# iospear310 register map
Registers from a debugger description file.
Registers are 32-bit, access not given, no defined reset value unless marked. A register's access mark holds for its fields unless they carry their own. Addresses are absolute; registers are grouped by the start of their names; lines under a group give offsets from that group; [hi:lo] are bit positions; {n}, {i} and the like mark numbered series; 'fields as' and 'values as' point back to an identical list; <NAME> marks a mode.

## PLL1
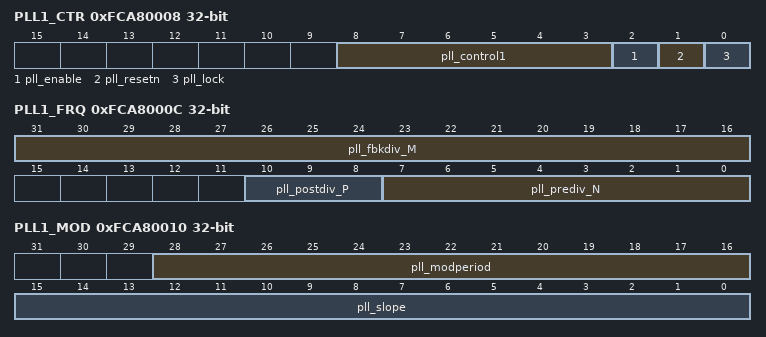
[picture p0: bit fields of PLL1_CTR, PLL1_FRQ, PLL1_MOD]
0xFCA80008 PLL1_CTR
  [8:3] pll_control1, [2] pll_enable, [1] pll_resetn, [0] pll_lock
0xFCA8000C PLL1_FRQ
  [31:16] pll_fbkdiv_M, [10:8] pll_postdiv_P, [7:0] pll_prediv_N
0xFCA80010 PLL1_MOD
  [28:16] pll_modperiod, [15:0] pll_slope

## PLL2
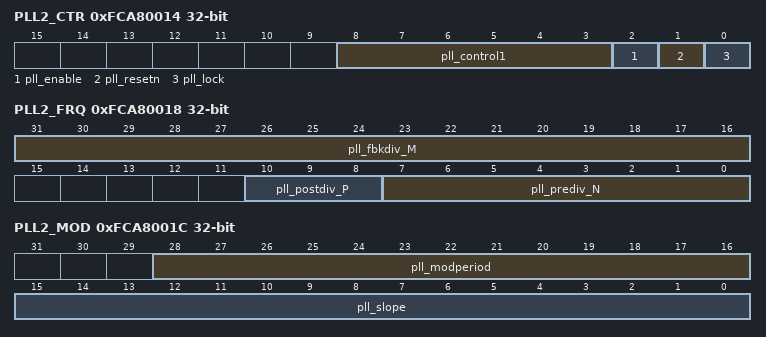
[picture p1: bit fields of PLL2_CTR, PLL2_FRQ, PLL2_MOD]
0xFCA80014 PLL2_CTR
  [8:3] pll_control1, [2] pll_enable, [1] pll_resetn, [0] pll_lock
0xFCA80018 PLL2_FRQ
  [31:16] pll_fbkdiv_M, [10:8] pll_postdiv_P, [7:0] pll_prediv_N
0xFCA8001C PLL2_MOD
  [28:16] pll_modperiod, [15:0] pll_slope

## PERIP1
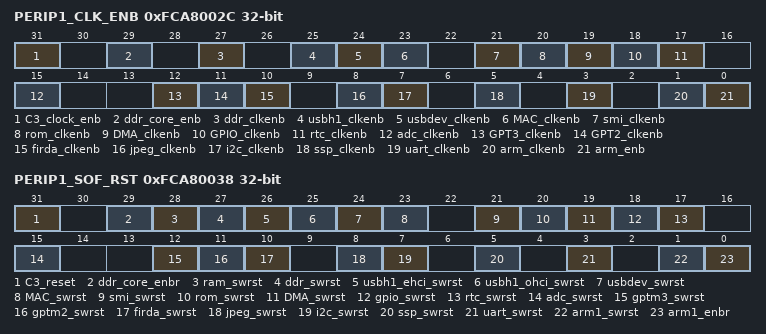
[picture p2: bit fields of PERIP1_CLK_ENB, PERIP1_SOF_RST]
0xFCA8002C PERIP1_CLK_ENB
  [31] C3_clock_enb, [29] ddr_core_enb, [27] ddr_clkenb, [25] usbh1_clkenb, [24] usbdev_clkenb, [23] MAC_clkenb, [21] smi_clkenb, [20] rom_clkenb, [19] DMA_clkenb, [18] GPIO_clkenb, [17] rtc_clkenb, [15] adc_clkenb, [12] GPT3_clkenb, [11] GPT2_clkenb, [10] firda_clkenb, [8] jpeg_clkenb, [7] i2c_clkenb, [5] ssp_clkenb, [3] uart_clkenb, [1] arm_clkenb, [0] arm_enb
0xFCA80038 PERIP1_SOF_RST
  [31] C3_reset, [29] ddr_core_enbr, [28] ram_swrst, [27] ddr_swrst, [26] usbh1_ehci_swrst, [25] usbh1_ohci_swrst, [24] usbdev_swrst, [23] MAC_swrst, [21] smi_swrst, [20] rom_swrst, [19] DMA_swrst, [18] gpio_swrst, [17] rtc_swrst, [15] adc_swrst, [12] gptm3_swrst, [11] gptm2_swrst, [10] firda_swrst, [8] jpeg_swrst, [7] i2c_swrst, [5] ssp_swrst, [3] uart_swrst, [1] arm1_swrst, [0] arm1_enbr

## RAS
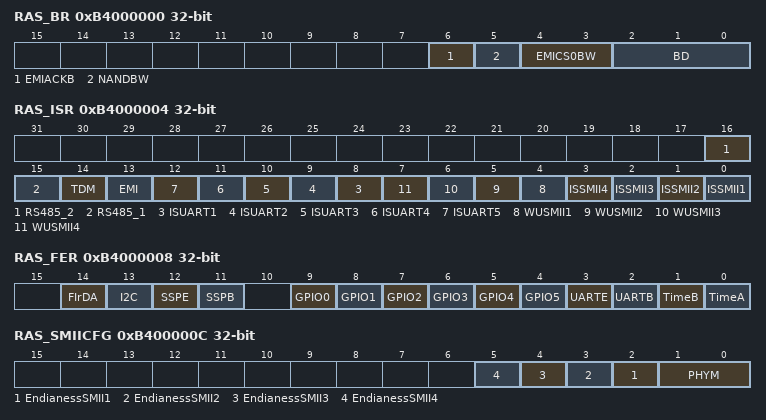
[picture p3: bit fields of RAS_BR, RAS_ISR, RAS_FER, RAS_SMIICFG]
0xB4000000 RAS_BR
  [6] EMIACKB, [5] NANDBW, [4:3] EMICS0BW, [2:0] BD
0xB4000004 RAS_ISR
  [16] RS485_2, [15] RS485_1, [14] TDM, [13] EMI, [n+7] ISUART{n} (n=1..5), [n+3] WUSMII{n} (n=1..4), [n-1] ISSMII{n} (n=1..4)
0xB4000008 RAS_FER
  [14] FIrDA, [13] I2C, [12] SSPE, [11] SSPB, [9-n] GPIO{n} (n=0..5), [3] UARTE, [2] UARTB, [1] TimeB, [0] TimeA
0xB400000C RAS_SMIICFG
  [n+1] EndianessSMII{n} (n=1..4), [1:0] PHYM
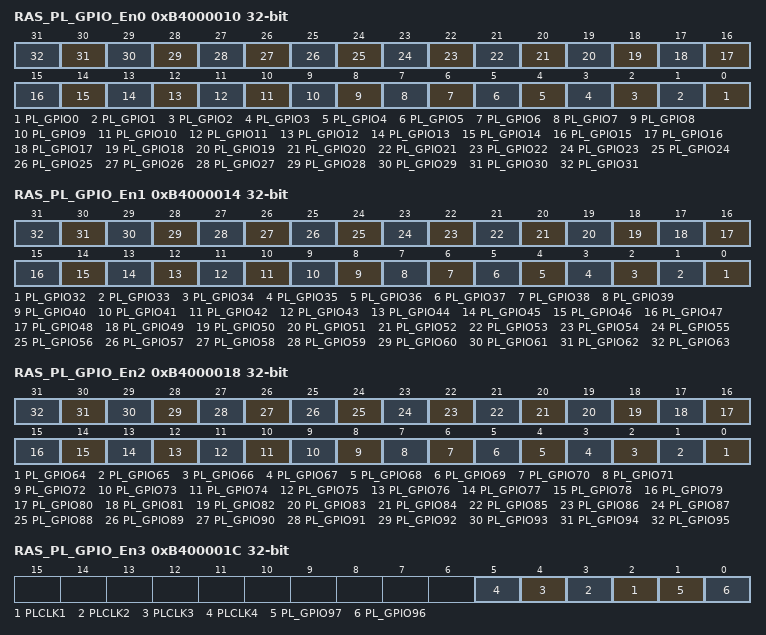
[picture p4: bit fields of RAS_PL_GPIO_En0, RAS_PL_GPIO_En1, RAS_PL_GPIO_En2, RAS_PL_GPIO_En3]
0xB4000010 RAS_PL_GPIO_En0
  [n] PL_GPIO{n} (n=0..31)
0xB4000014 RAS_PL_GPIO_En1
  [n-32] PL_GPIO{n} (n=32..63)
0xB4000018 RAS_PL_GPIO_En2
  [n-64] PL_GPIO{n} (n=64..95)
0xB400001C RAS_PL_GPIO_En3
  [n+1] PLCLK{n} (n=1..4), [1] PL_GPIO97, [0] PL_GPIO96
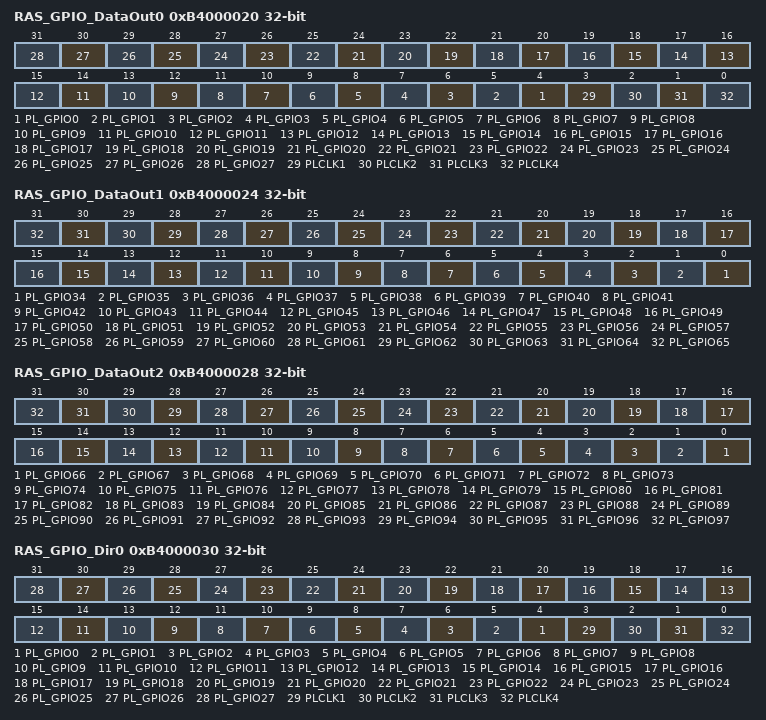
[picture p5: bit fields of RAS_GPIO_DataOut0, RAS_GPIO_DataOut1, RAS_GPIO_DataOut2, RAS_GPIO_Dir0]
0xB4000020 RAS_GPIO_DataOut0
  [n+4] PL_GPIO{n} (n=0..27), [4-n] PLCLK{n} (n=1..4)
0xB4000024 RAS_GPIO_DataOut1
  [n-34] PL_GPIO{n} (n=34..65)
0xB4000028 RAS_GPIO_DataOut2
  [n-66] PL_GPIO{n} (n=66..97)
0xB4000030 RAS_GPIO_Dir0
  [n+4] PL_GPIO{n} (n=0..27), [4-n] PLCLK{n} (n=1..4)
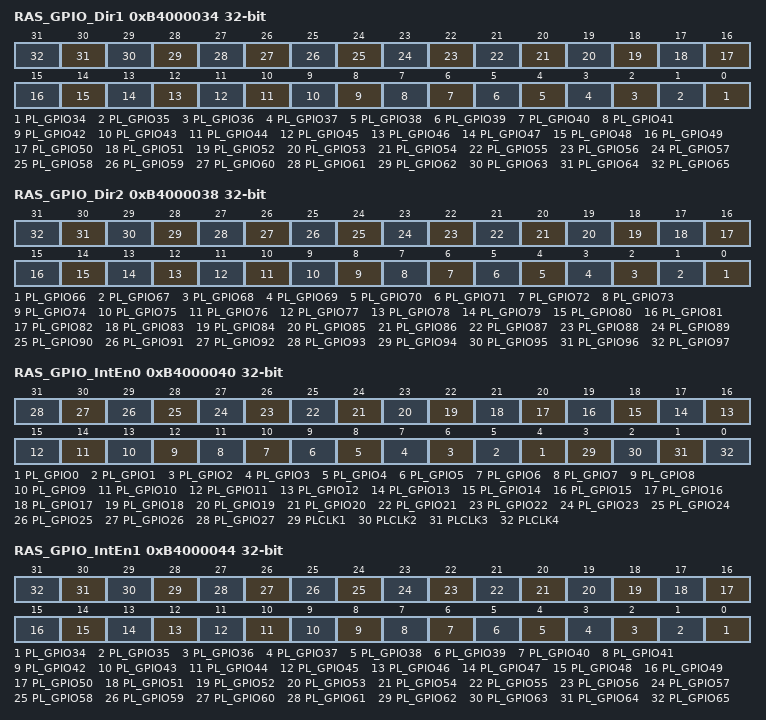
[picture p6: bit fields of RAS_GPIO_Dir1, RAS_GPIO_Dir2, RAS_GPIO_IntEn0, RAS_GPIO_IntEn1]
0xB4000034 RAS_GPIO_Dir1
  [n-34] PL_GPIO{n} (n=34..65)
0xB4000038 RAS_GPIO_Dir2
  [n-66] PL_GPIO{n} (n=66..97)
0xB4000040 RAS_GPIO_IntEn0
  [n+4] PL_GPIO{n} (n=0..27), [4-n] PLCLK{n} (n=1..4)
0xB4000044 RAS_GPIO_IntEn1
  [n-34] PL_GPIO{n} (n=34..65)
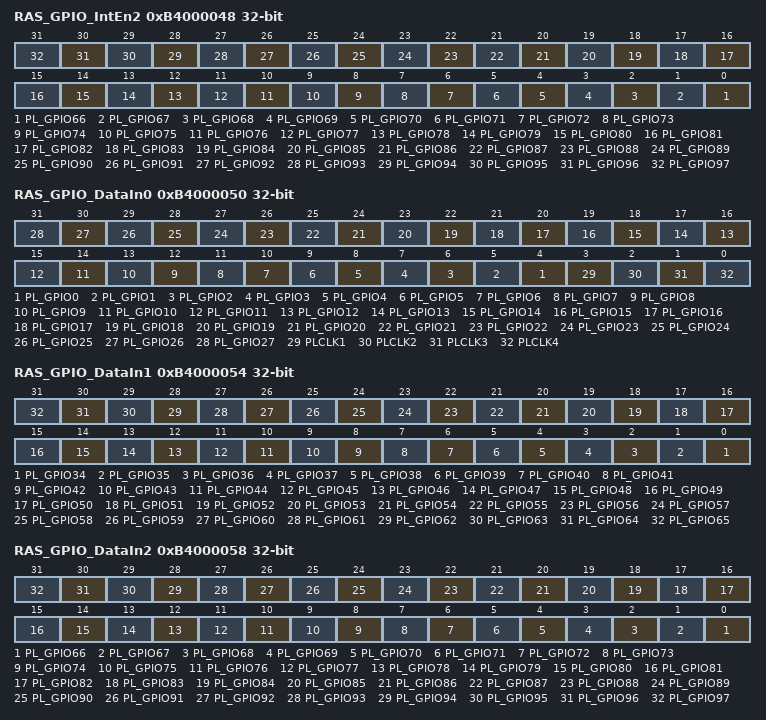
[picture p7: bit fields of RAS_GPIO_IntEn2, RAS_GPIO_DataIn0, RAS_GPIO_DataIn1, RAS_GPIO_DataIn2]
0xB4000048 RAS_GPIO_IntEn2
  [n-66] PL_GPIO{n} (n=66..97)
0xB4000050 RAS_GPIO_DataIn0
  [n+4] PL_GPIO{n} (n=0..27), [4-n] PLCLK{n} (n=1..4)
0xB4000054 RAS_GPIO_DataIn1
  [n-34] PL_GPIO{n} (n=34..65)
0xB4000058 RAS_GPIO_DataIn2
  [n-66] PL_GPIO{n} (n=66..97)
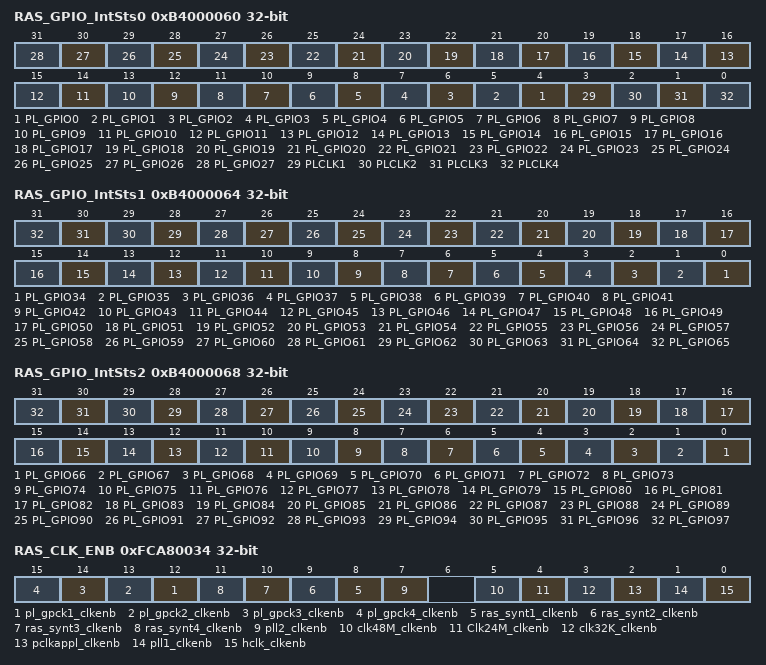
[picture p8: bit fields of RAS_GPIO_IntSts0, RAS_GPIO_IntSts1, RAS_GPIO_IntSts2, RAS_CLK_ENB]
0xB4000060 RAS_GPIO_IntSts0
  [n+4] PL_GPIO{n} (n=0..27), [4-n] PLCLK{n} (n=1..4)
0xB4000064 RAS_GPIO_IntSts1
  [n-34] PL_GPIO{n} (n=34..65)
0xB4000068 RAS_GPIO_IntSts2
  [n-66] PL_GPIO{n} (n=66..97)
0xFCA80034 RAS_CLK_ENB
  [n+11] pl_gpck{n}_clkenb (n=1..4), [n+7] ras_synt{n}_clkenb (n=1..4), [7] pll2_clkenb, [5] clk48M_clkenb, [4] Clk24M_clkenb, [3] clk32K_clkenb, [2] pclkappl_clkenb, [1] pll1_clkenb, [0] hclk_clkenb
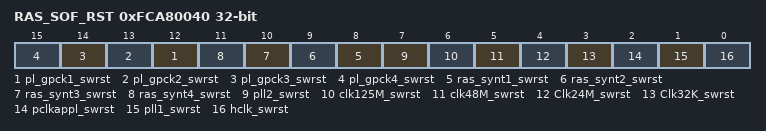
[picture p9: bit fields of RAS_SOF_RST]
0xFCA80040 RAS_SOF_RST
  [n+11] pl_gpck{n}_swrst (n=1..4), [n+7] ras_synt{n}_swrst (n=1..4), [7] pll2_swrst, [6] clk125M_swrst, [5] clk48M_swrst, [4] Clk24M_swrst, [3] Clk32K_swrst, [2] pclkappl_swrst, [1] pll1_swrst, [0] hclk_swrst
